# ATA6613C device description
Architecture: AVR8; Family: megaAVR
Registers are 8-bit, access not given, no defined reset value unless marked. A register's access mark holds for its fields unless they carry their own. Offsets are from the block's base; [hi:lo] are bit positions.

## USART0
Instances: USART0 0x00
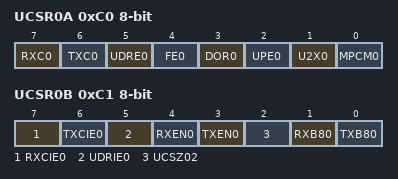
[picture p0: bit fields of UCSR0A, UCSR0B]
0xC0 UCSR0A — USART Control and Status Register A
  [7] RXC0 — USART Receive Complete
  [6] TXC0 — USART Transmitt Complete
  [5] UDRE0 — USART Data Register Empty
  [4] FE0 — Framing Error
  [3] DOR0 — Data overRun
  [2] UPE0 — Parity Error
  [1] U2X0 — Double the USART transmission speed
  [0] MPCM0 — Multi-processor Communication Mode
0xC1 UCSR0B — USART Control and Status Register B
  [7] RXCIE0 — RX Complete Interrupt Enable
  [6] TXCIE0 — TX Complete Interrupt Enable
  [5] UDRIE0 — USART Data register Empty Interrupt Enable
  [4] RXEN0 — Receiver Enable
  [3] TXEN0 — Transmitter Enable
  [2] UCSZ02 — Character Size
  [1] RXB80 — Receive Data Bit 8
  [0] TXB80 — Transmit Data Bit 8
0xC2 UCSR0C — USART Control and Status Register C
  [7:6] UMSEL0 — USART Mode Select
    0=Asynchronous USART; 1=Synchronous USART; 3=Master SPI
  [5:4] UPM0 — Parity Mode Bits
    0=Disabled; 2=Enabled, Even Parity; 3=Enabled, Odd Parity
  [3] USBS0 — Stop Bit Select
    0=1-bit; 1=2-bit
  [2] UDORD0 — Data Order
  [2:1] UCSZ0 — Character Size
  [1] UCPHA0 — Clock Phase
  [0] UCPOL0 — Clock Polarity
0xC4 UBRR0 16-bit bits used 11:0 — USART Baud Rate Register Bytes
0xC6 UDR0 — USART I/O Data Register

## TWI
Instances: TWI 0x00
0xB8 TWBR — TWI Bit Rate register
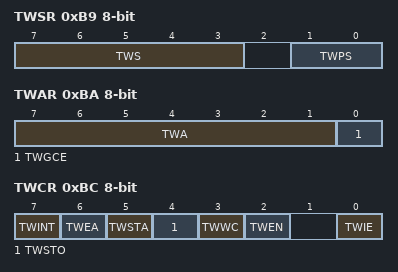
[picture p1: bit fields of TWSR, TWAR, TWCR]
0xB9 TWSR — TWI Status Register
  [7:3] TWS (bit 3 of the value upward) — TWI Status
  [1:0] TWPS — TWI Prescaler
    0=1; 1=4; 2=16; 3=64
0xBA TWAR — TWI (Slave) Address register
  [7:1] TWA — TWI (Slave) Address register Bits
  [0] TWGCE — TWI General Call Recognition Enable Bit
0xBB TWDR — TWI Data register
0xBC TWCR — TWI Control Register
  [7] TWINT — TWI Interrupt Flag
  [6] TWEA — TWI Enable Acknowledge Bit
  [5] TWSTA — TWI Start Condition Bit
  [4] TWSTO — TWI Stop Condition Bit
  [3] TWWC — TWI Write Collition Flag
  [2] TWEN — TWI Enable Bit
  [0] TWIE — TWI Interrupt Enable
0xBD TWAMR — TWI (Slave) Address Mask Register
  [7:1] TWAM

## TIMER_COUNTER_1
Instances: TIMER_COUNTER_1 0x00
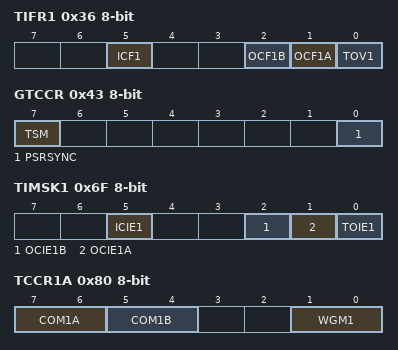
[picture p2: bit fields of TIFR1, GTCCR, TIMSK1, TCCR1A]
0x36 TIFR1 — Timer/Counter Interrupt Flag register
  [5] ICF1 — Input Capture Flag 1
  [2] OCF1B — Output Compare Flag 1B
  [1] OCF1A — Output Compare Flag 1A
  [0] TOV1 — Timer/Counter1 Overflow Flag
0x43 GTCCR — General Timer/Counter Control Register
  [7] TSM — Timer/Counter Synchronization Mode
  [0] PSRSYNC — Prescaler Reset Timer/Counter1 and Timer/Counter0
0x6F TIMSK1 — Timer/Counter Interrupt Mask Register
  [5] ICIE1 — Timer/Counter1 Input Capture Interrupt Enable
  [2] OCIE1B — Timer/Counter1 Output CompareB Match Interrupt Enable
  [1] OCIE1A — Timer/Counter1 Output CompareA Match Interrupt Enable
  [0] TOIE1 — Timer/Counter1 Overflow Interrupt Enable
0x80 TCCR1A — Timer/Counter1 Control Register A
  [7:6] COM1A — Compare Output Mode 1A, bits
  [5:4] COM1B — Compare Output Mode 1B, bits
  [1:0] WGM1 — Waveform Generation Mode
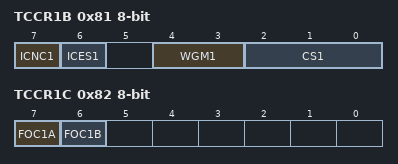
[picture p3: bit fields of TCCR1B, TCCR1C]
0x81 TCCR1B — Timer/Counter1 Control Register B
  [7] ICNC1 — Input Capture 1 Noise Canceler
  [6] ICES1 — Input Capture 1 Edge Select
  [4:3] WGM1 (bit 2 of the value upward) — Waveform Generation Mode
  [2:0] CS1 — Prescaler source of Timer/Counter 1
    0=No Clock Source (Stopped); 1=Running, No Prescaling; 2=Running, CLK/8; 3=Running, CLK/64; 4=Running, CLK/256; 5=Running, CLK/1024; 6=Running, ExtClk Tx Falling Edge; 7=Running, ExtClk Tx Rising Edge
0x82 TCCR1C — Timer/Counter1 Control Register C
  [7] FOC1A, [6] FOC1B
0x84 TCNT1 16-bit — Timer/Counter1 Bytes
0x86 ICR1 16-bit — Timer/Counter1 Input Capture Register Bytes
0x88 OCR1A 16-bit — Timer/Counter1 Output Compare Register Bytes
0x8A OCR1B 16-bit — Timer/Counter1 Output Compare Register Bytes

## TIMER_COUNTER_2
Instances: TIMER_COUNTER_2 0x00
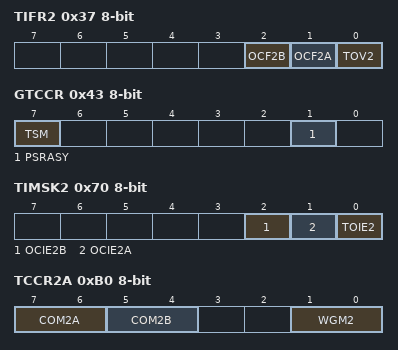
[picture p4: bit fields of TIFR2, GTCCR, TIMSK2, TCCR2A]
0x37 TIFR2 — Timer/Counter Interrupt Flag Register
  [2] OCF2B — Output Compare Flag 2B
  [1] OCF2A — Output Compare Flag 2A
  [0] TOV2 — Timer/Counter2 Overflow Flag
0x43 GTCCR — General Timer Counter Control register
  [7] TSM — Timer/Counter Synchronization Mode
  [1] PSRASY — Prescaler Reset Timer/Counter2
0x70 TIMSK2 — Timer/Counter Interrupt Mask register
  [2] OCIE2B — Timer/Counter2 Output Compare Match B Interrupt Enable
  [1] OCIE2A — Timer/Counter2 Output Compare Match A Interrupt Enable
  [0] TOIE2 — Timer/Counter2 Overflow Interrupt Enable
0xB0 TCCR2A — Timer/Counter2 Control Register A
  [7:6] COM2A — Compare Output Mode bits
  [5:4] COM2B — Compare Output Mode bits
  [1:0] WGM2 — Waveform Genration Mode
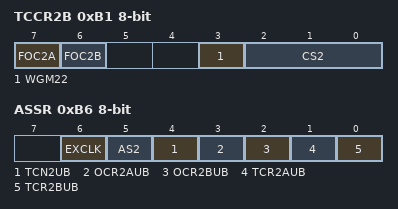
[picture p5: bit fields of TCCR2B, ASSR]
0xB1 TCCR2B — Timer/Counter2 Control Register B
  [7] FOC2A — Force Output Compare A
  [6] FOC2B — Force Output Compare B
  [3] WGM22 — Waveform Generation Mode
  [2:0] CS2 — Clock Select bits
    0=No Clock Source (Stopped); 1=Running, No Prescaling; 2=Running, CLK/8; 3=Running, CLK/32; 4=Running, CLK/64; 5=Running, CLK/128; 6=Running, CLK/256; 7=Running, CLK/1024
0xB2 TCNT2 — Timer/Counter2
0xB3 OCR2A — Timer/Counter2 Output Compare Register A
0xB4 OCR2B — Timer/Counter2 Output Compare Register B
0xB6 ASSR — Asynchronous Status Register
  [6] EXCLK — Enable External Clock Input
  [5] AS2 — Asynchronous Timer/Counter2
  [4] TCN2UB — Timer/Counter2 Update Busy
  [3] OCR2AUB — Output Compare Register2 Update Busy
  [2] OCR2BUB — Output Compare Register 2 Update Busy
  [1] TCR2AUB — Timer/Counter Control Register2 Update Busy
  [0] TCR2BUB — Timer/Counter Control Register2 Update Busy
